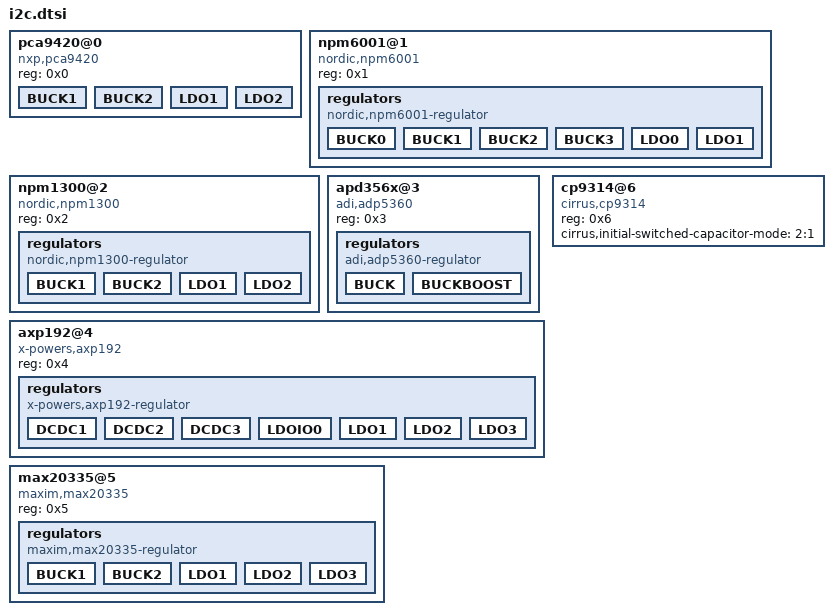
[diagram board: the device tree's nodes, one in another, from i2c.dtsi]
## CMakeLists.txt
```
# Copyright (c) 2023 Nordic Semiconductor ASA
# SPDX-License-Identifier: Apache-2.0

cmake_minimum_required(VERSION 3.20.0)
find_package(Zephyr REQUIRED HINTS $ENV{ZEPHYR_BASE})
project(build_all)

target_sources(app PRIVATE src/main.c)
```

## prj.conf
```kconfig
CONFIG_REGULATOR=y
```

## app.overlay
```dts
/*
 * Copyright (c) 2023 Nordic Semiconductor ASA
 * SPDX-License-Identifier: Apache-2.0
 */

/ {
	test {
		#address-cells = <1>;
		#size-cells = <1>;

		test_i2c: i2c@11112222 {
			#address-cells = <1>;
			#size-cells = <0>;
			compatible = "vnd,i2c";
			reg = <0x11112222 0x1000>;
			status = "okay";
			clock-frequency = <100000>;

			#include "i2c.dtsi"
		};

		test_gpio: gpio@deadbeef {
			compatible = "vnd,gpio";
			gpio-controller;
			reg = <0xdeadbeef 0x1000>;
			#gpio-cells = <0x2>;
			status = "okay";
		};

		#include "misc.dtsi"
	};
};
```

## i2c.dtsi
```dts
/*
 * Copyright (c) 2023 Nordic Semiconductor ASA
 * SPDX-License-Identifier: Apache-2.0
 */

/****************************************
 * PLEASE KEEP REG ADDRESSES SEQUENTIAL *
 ***************************************/

pca9420@0 {
	compatible = "nxp,pca9420";
	reg = <0x0>;

	BUCK1 {};
	BUCK2 {};
	LDO1 {};
	LDO2 {};
};

npm6001@1 {
	compatible = "nordic,npm6001";
	reg = <0x1>;

	regulators {
		compatible = "nordic,npm6001-regulator";

		BUCK0 {};
		BUCK1 {};
		BUCK2 {};
		BUCK3 {};
		LDO0 {};
		LDO1 {};
	};
};

npm1300@2 {
	compatible = "nordic,npm1300";
	reg = <0x2>;

	regulators {
		compatible = "nordic,npm1300-regulator";

		BUCK1 {};
		BUCK2 {};
		LDO1 {};
		LDO2 {};
	};
};

apd356x@3 {
	compatible = "adi,adp5360";
	reg = <0x3>;

	regulators {
		compatible = "adi,adp5360-regulator";

		BUCK {};
		BUCKBOOST {};
	};
};

axp192@4 {
	compatible = "x-powers,axp192";
	reg = <0x4>;

	regulators {
		compatible = "x-powers,axp192-regulator";

		DCDC1 {};
		DCDC2 {};
		DCDC3 {};
		LDOIO0 {};
		LDO1 {};
		LDO2 {};
		LDO3 {};
	};
};

max20335@5 {
	compatible = "maxim,max20335";
	reg = <0x5>;

	regulators {
		compatible = "maxim,max20335-regulator";

		BUCK1 {};
		BUCK2 {};
		LDO1 {};
		LDO2 {};
		LDO3 {};
	};
};

cp9314@6 {
	compatible = "cirrus,cp9314";
	reg = <0x6>;

	cirrus,initial-switched-capacitor-mode = "2:1";
};
```

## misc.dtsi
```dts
/*
 * Copyright (c) 2023 Nordic Semiconductor ASA
 * SPDX-License-Identifier: Apache-2.0
 */

regulator-fixed {
	compatible = "regulator-fixed";
	regulator-name = "test";
	enable-gpios = <&test_gpio 0 GPIO_ACTIVE_HIGH>;
};

npm1100 {
	compatible = "nordic,npm1100";

	BUCK {};
};
```

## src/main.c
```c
/*
 * Copyright (c) 2023 Nordic Semiconductor ASA
 * SPDX-License-Identifier: Apache-2.0
 */

int main(void)
{
	return 0;
}
```
